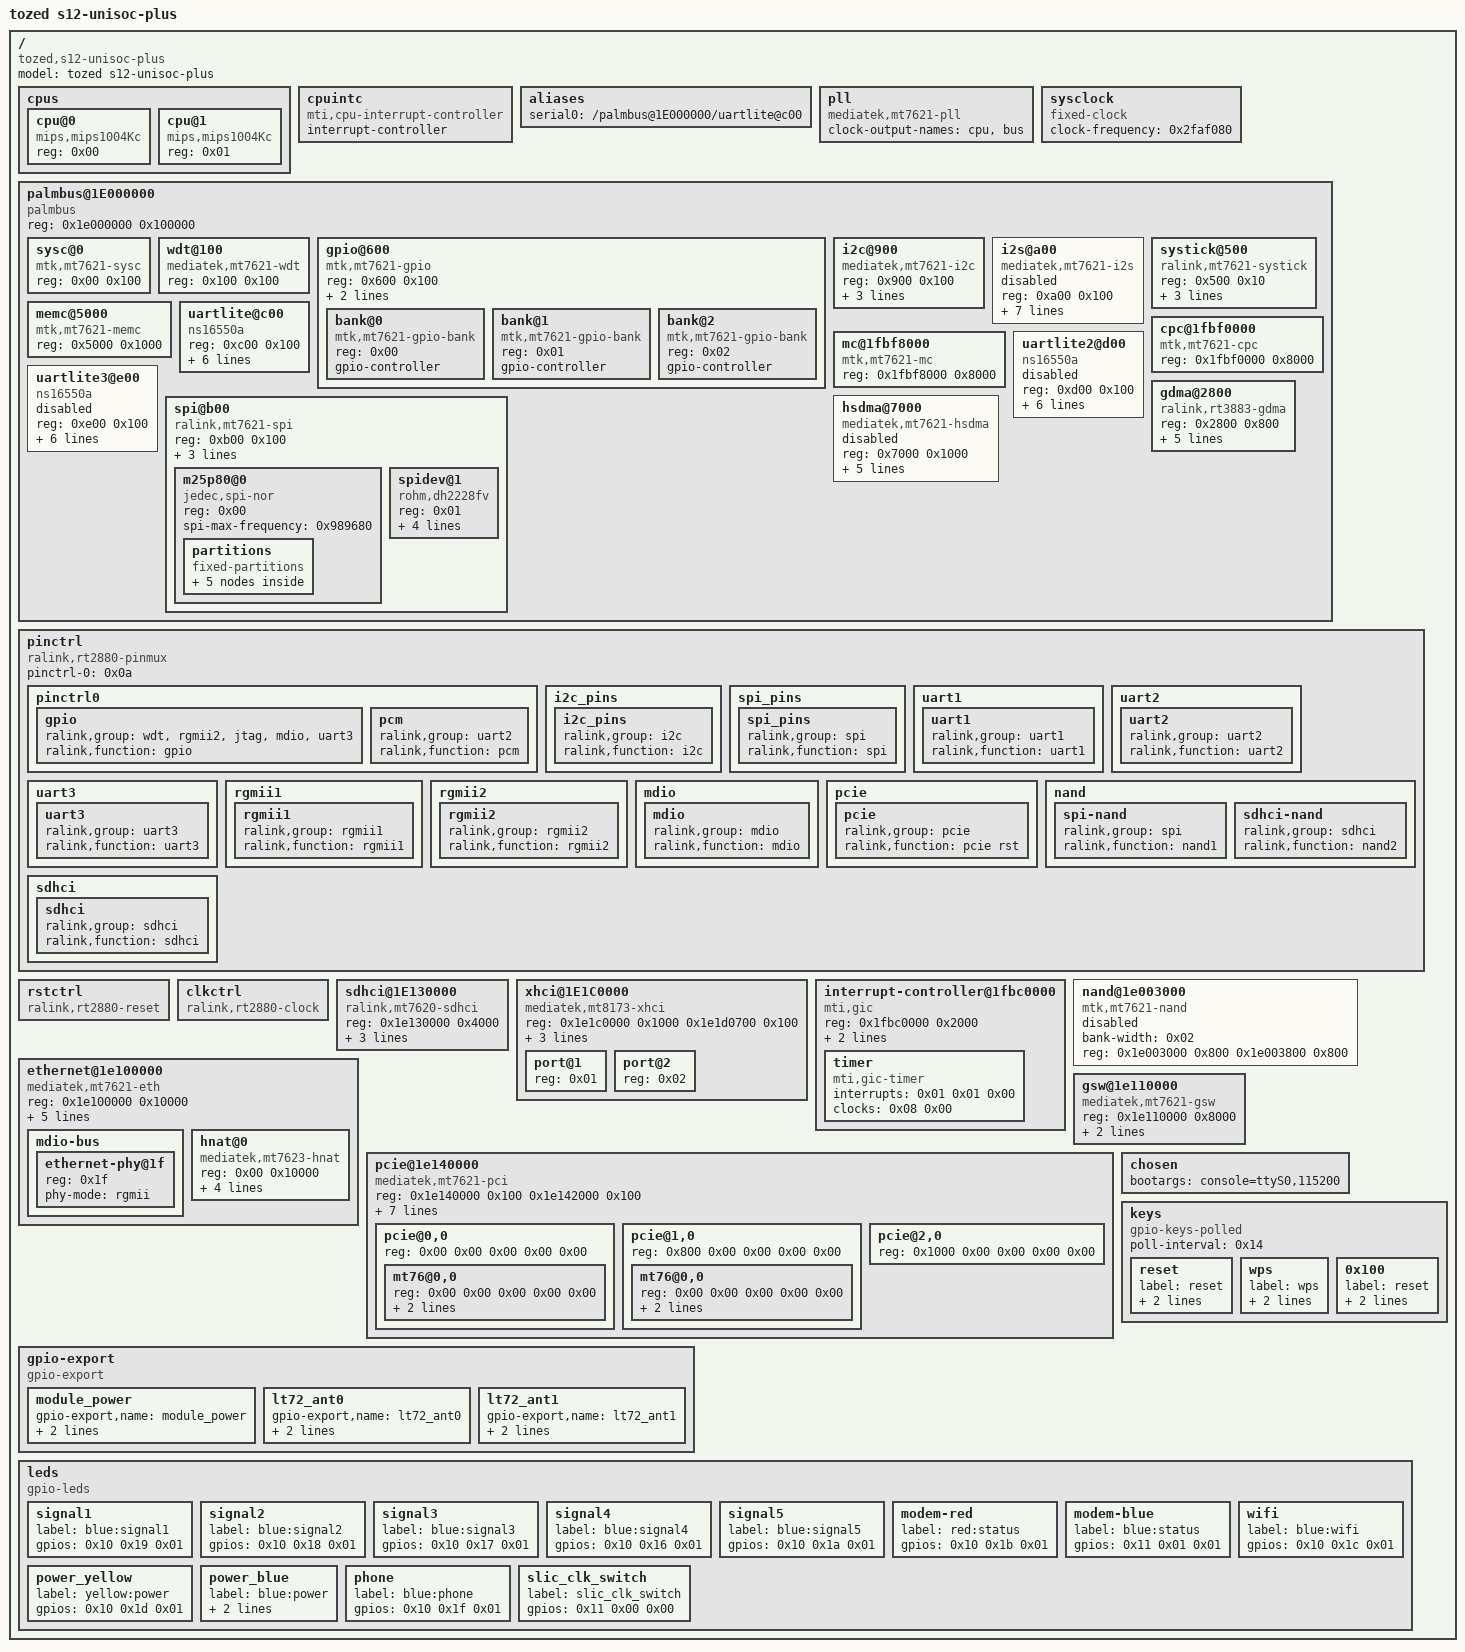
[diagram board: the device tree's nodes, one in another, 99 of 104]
/dts-v1/;

/ {
	#address-cells = <0x01>;
	#size-cells = <0x01>;
	compatible = "tozed,s12-unisoc-plus", "mediatek,mt7621-soc";
	model = "tozed s12-unisoc-plus";

	cpus {
		#address-cells = <0x01>;
		#size-cells = <0x00>;

		cpu@0 {
			device_type = "cpu";
			compatible = "mips,mips1004Kc";
			reg = <0x00>;
		};

		cpu@1 {
			device_type = "cpu";
			compatible = "mips,mips1004Kc";
			reg = <0x01>;
		};
	};

	cpuintc {
		#address-cells = <0x00>;
		#interrupt-cells = <0x01>;
		interrupt-controller;
		compatible = "mti,cpu-interrupt-controller";
	};

	aliases {
		serial0 = "/palmbus@1E000000/uartlite@c00";
	};

	pll {
		compatible = "mediatek,mt7621-pll", "syscon";
		#clock-cells = <0x01>;
		clock-output-names = "cpu", "bus";
		linux,phandle = <0x08>;
		phandle = <0x08>;
	};

	sysclock {
		#clock-cells = <0x00>;
		compatible = "fixed-clock";
		clock-frequency = <0x2faf080>;
		linux,phandle = <0x02>;
		phandle = <0x02>;
	};

	palmbus@1E000000 {
		compatible = "palmbus";
		reg = <0x1e000000 0x100000>;
		ranges = <0x00 0x1e000000 0xfffff>;
		#address-cells = <0x01>;
		#size-cells = <0x01>;

		sysc@0 {
			compatible = "mtk,mt7621-sysc";
			reg = <0x00 0x100>;
		};

		wdt@100 {
			compatible = "mediatek,mt7621-wdt";
			reg = <0x100 0x100>;
		};

		gpio@600 {
			#address-cells = <0x01>;
			#size-cells = <0x00>;
			compatible = "mtk,mt7621-gpio";
			reg = <0x600 0x100>;
			interrupt-parent = <0x01>;
			interrupts = <0x00 0x0c 0x04>;

			bank@0 {
				reg = <0x00>;
				compatible = "mtk,mt7621-gpio-bank";
				gpio-controller;
				#gpio-cells = <0x02>;
				linux,phandle = <0x10>;
				phandle = <0x10>;
			};

			bank@1 {
				reg = <0x01>;
				compatible = "mtk,mt7621-gpio-bank";
				gpio-controller;
				#gpio-cells = <0x02>;
				linux,phandle = <0x11>;
				phandle = <0x11>;
			};

			bank@2 {
				reg = <0x02>;
				compatible = "mtk,mt7621-gpio-bank";
				gpio-controller;
				#gpio-cells = <0x02>;
			};
		};

		i2c@900 {
			compatible = "mediatek,mt7621-i2c";
			reg = <0x900 0x100>;
			clocks = <0x02>;
			resets = <0x03 0x10>;
			reset-names = "i2c";
			#address-cells = <0x01>;
			#size-cells = <0x00>;
			status = "okay";
			pinctrl-names = "default";
			pinctrl-0 = <0x04>;
		};

		i2s@a00 {
			compatible = "mediatek,mt7621-i2s";
			reg = <0xa00 0x100>;
			clocks = <0x02>;
			resets = <0x03 0x11>;
			reset-names = "i2s";
			interrupt-parent = <0x01>;
			interrupts = <0x00 0x10 0x04>;
			txdma-req = <0x02>;
			rxdma-req = <0x03>;
			dmas = <0x05 0x04 0x05 0x06>;
			dma-names = "tx", "rx";
			status = "disabled";
		};

		systick@500 {
			compatible = "ralink,mt7621-systick", "ralink,cevt-systick";
			reg = <0x500 0x10>;
			resets = <0x03 0x1c>;
			reset-names = "intc";
			interrupt-parent = <0x01>;
			interrupts = <0x00 0x05 0x04>;
		};

		memc@5000 {
			compatible = "mtk,mt7621-memc";
			reg = <0x5000 0x1000>;
		};

		cpc@1fbf0000 {
			compatible = "mtk,mt7621-cpc";
			reg = <0x1fbf0000 0x8000>;
		};

		mc@1fbf8000 {
			compatible = "mtk,mt7621-mc";
			reg = <0x1fbf8000 0x8000>;
		};

		uartlite@c00 {
			compatible = "ns16550a";
			reg = <0xc00 0x100>;
			clock-frequency = <0x2faf080>;
			interrupt-parent = <0x01>;
			interrupts = <0x00 0x1a 0x04>;
			reg-shift = <0x02>;
			reg-io-width = <0x04>;
			no-loopback-test;
		};

		uartlite2@d00 {
			compatible = "ns16550a";
			reg = <0xd00 0x100>;
			clock-frequency = <0x2faf080>;
			interrupt-parent = <0x01>;
			interrupts = <0x00 0x1b 0x04>;
			reg-shift = <0x02>;
			reg-io-width = <0x04>;
			pinctrl-names = "default";
			pinctrl-0 = <0x06>;
			status = "disabled";
		};

		uartlite3@e00 {
			compatible = "ns16550a";
			reg = <0xe00 0x100>;
			clock-frequency = <0x2faf080>;
			interrupt-parent = <0x01>;
			interrupts = <0x00 0x1c 0x04>;
			reg-shift = <0x02>;
			reg-io-width = <0x04>;
			pinctrl-names = "default";
			pinctrl-0 = <0x07>;
			status = "disabled";
		};

		spi@b00 {
			status = "okay";
			compatible = "ralink,mt7621-spi";
			reg = <0xb00 0x100>;
			clocks = <0x08 0x01>;
			resets = <0x03 0x12>;
			reset-names = "spi";
			#address-cells = <0x01>;
			#size-cells = <0x00>;
			pinctrl-names = "default";
			pinctrl-0 = <0x09>;

			m25p80@0 {
				compatible = "jedec,spi-nor";
				reg = <0x00>;
				spi-max-frequency = <0x989680>;

				partitions {
					compatible = "fixed-partitions";
					#address-cells = <0x01>;
					#size-cells = <0x01>;

					partition@0 {
						label = "u-boot";
						reg = <0x00 0x30000>;
						read-only;
					};

					partition@30000 {
						label = "u-boot-env";
						reg = <0x30000 0x8000>;
					};

					partition@40000 {
						label = "factory";
						reg = <0x40000 0x10000>;
						linux,phandle = <0x0d>;
						phandle = <0x0d>;
					};

					partition@50000 {
						compatible = "denx,uimage";
						label = "firmware";
						reg = <0x50000 0xfb0000>;
					};

					partition@38000 {
						label = "tozed-conf";
						reg = <0x38000 0x8000>;
					};
				};
			};

			spidev@1 {
				compatible = "rohm,dh2228fv";
				reg = <0x01>;
				linux,modalias = "spidev";
				spi-cpha = <0x01>;
				spi-cpol = <0x01>;
				status = "okay";
				spi-max-frequency = <0x1f4000>;
			};
		};

		gdma@2800 {
			compatible = "ralink,rt3883-gdma";
			reg = <0x2800 0x800>;
			resets = <0x03 0x0e>;
			reset-names = "dma";
			interrupt-parent = <0x01>;
			interrupts = <0x00 0x0d 0x04>;
			#dma-cells = <0x01>;
			#dma-channels = <0x10>;
			#dma-requests = <0x10>;
			status = "okay";
			linux,phandle = <0x05>;
			phandle = <0x05>;
		};

		hsdma@7000 {
			compatible = "mediatek,mt7621-hsdma";
			reg = <0x7000 0x1000>;
			resets = <0x03 0x05>;
			reset-names = "hsdma";
			interrupt-parent = <0x01>;
			interrupts = <0x00 0x0b 0x04>;
			#dma-cells = <0x01>;
			#dma-channels = <0x01>;
			#dma-requests = <0x01>;
			status = "disabled";
		};
	};

	pinctrl {
		compatible = "ralink,rt2880-pinmux";
		pinctrl-names = "default";
		pinctrl-0 = <0x0a>;

		pinctrl0 {
			linux,phandle = <0x0a>;
			phandle = <0x0a>;

			gpio {
				ralink,group = "wdt", "rgmii2", "jtag", "mdio", "uart3";
				ralink,function = "gpio";
			};

			pcm {
				ralink,group = "uart2";
				ralink,function = "pcm";
			};
		};

		i2c_pins {
			linux,phandle = <0x04>;
			phandle = <0x04>;

			i2c_pins {
				ralink,group = "i2c";
				ralink,function = "i2c";
			};
		};

		spi_pins {
			linux,phandle = <0x09>;
			phandle = <0x09>;

			spi_pins {
				ralink,group = "spi";
				ralink,function = "spi";
			};
		};

		uart1 {

			uart1 {
				ralink,group = "uart1";
				ralink,function = "uart1";
			};
		};

		uart2 {
			linux,phandle = <0x06>;
			phandle = <0x06>;

			uart2 {
				ralink,group = "uart2";
				ralink,function = "uart2";
			};
		};

		uart3 {
			linux,phandle = <0x07>;
			phandle = <0x07>;

			uart3 {
				ralink,group = "uart3";
				ralink,function = "uart3";
			};
		};

		rgmii1 {

			rgmii1 {
				ralink,group = "rgmii1";
				ralink,function = "rgmii1";
			};
		};

		rgmii2 {

			rgmii2 {
				ralink,group = "rgmii2";
				ralink,function = "rgmii2";
			};
		};

		mdio {

			mdio {
				ralink,group = "mdio";
				ralink,function = "mdio";
			};
		};

		pcie {
			linux,phandle = <0x0e>;
			phandle = <0x0e>;

			pcie {
				ralink,group = "pcie";
				ralink,function = "pcie rst";
			};
		};

		nand {

			spi-nand {
				ralink,group = "spi";
				ralink,function = "nand1";
			};

			sdhci-nand {
				ralink,group = "sdhci";
				ralink,function = "nand2";
			};
		};

		sdhci {
			linux,phandle = <0x0b>;
			phandle = <0x0b>;

			sdhci {
				ralink,group = "sdhci";
				ralink,function = "sdhci";
			};
		};
	};

	rstctrl {
		compatible = "ralink,rt2880-reset";
		#reset-cells = <0x01>;
		linux,phandle = <0x03>;
		phandle = <0x03>;
	};

	clkctrl {
		compatible = "ralink,rt2880-clock";
		#clock-cells = <0x01>;
		linux,phandle = <0x0f>;
		phandle = <0x0f>;
	};

	sdhci@1E130000 {
		status = "okay";
		compatible = "ralink,mt7620-sdhci";
		reg = <0x1e130000 0x4000>;
		interrupt-parent = <0x01>;
		interrupts = <0x00 0x14 0x04>;
		pinctrl-names = "default";
		pinctrl-0 = <0x0b>;
	};

	xhci@1E1C0000 {
		#address-cells = <0x01>;
		#size-cells = <0x00>;
		status = "okay";
		compatible = "mediatek,mt8173-xhci";
		reg = <0x1e1c0000 0x1000 0x1e1d0700 0x100>;
		reg-names = "mac", "ippc";
		clocks = <0x02>;
		clock-names = "sys_ck";
		interrupt-parent = <0x01>;
		interrupts = <0x00 0x16 0x04>;

		port@1 {
			reg = <0x01>;
			#trigger-source-cells = <0x00>;
		};

		port@2 {
			reg = <0x02>;
			#trigger-source-cells = <0x00>;
		};
	};

	interrupt-controller@1fbc0000 {
		compatible = "mti,gic";
		reg = <0x1fbc0000 0x2000>;
		interrupt-controller;
		#interrupt-cells = <0x03>;
		mti,reserved-cpu-vectors = <0x07>;
		linux,phandle = <0x01>;
		phandle = <0x01>;

		timer {
			compatible = "mti,gic-timer";
			interrupts = <0x01 0x01 0x00>;
			clocks = <0x08 0x00>;
		};
	};

	nand@1e003000 {
		status = "disabled";
		compatible = "mtk,mt7621-nand";
		bank-width = <0x02>;
		reg = <0x1e003000 0x800 0x1e003800 0x800>;
	};

	ethernet@1e100000 {
		compatible = "mediatek,mt7621-eth";
		reg = <0x1e100000 0x10000>;
		#address-cells = <0x01>;
		#size-cells = <0x01>;
		resets = <0x03 0x06 0x03 0x17>;
		reset-names = "fe", "eth";
		interrupt-parent = <0x01>;
		interrupts = <0x00 0x03 0x04>;
		mediatek,switch = <0x0c>;
		mtd-mac-address = <0x0d 0xe000>;

		mdio-bus {
			#address-cells = <0x01>;
			#size-cells = <0x00>;

			ethernet-phy@1f {
				reg = <0x1f>;
				phy-mode = "rgmii";
			};
		};

		hnat@0 {
			compatible = "mediatek,mt7623-hnat";
			reg = <0x00 0x10000>;
			mtketh-ppd = "eth0";
			mtketh-lan = "eth0";
			mtketh-wan = "eth0";
			resets = <0x03 0x00>;
			reset-names = "mtketh";
		};
	};

	gsw@1e110000 {
		compatible = "mediatek,mt7621-gsw";
		reg = <0x1e110000 0x8000>;
		interrupt-parent = <0x01>;
		interrupts = <0x00 0x17 0x04>;
		linux,phandle = <0x0c>;
		phandle = <0x0c>;
	};

	pcie@1e140000 {
		compatible = "mediatek,mt7621-pci";
		reg = <0x1e140000 0x100 0x1e142000 0x100>;
		#address-cells = <0x03>;
		#size-cells = <0x02>;
		pinctrl-names = "default";
		pinctrl-0 = <0x0e>;
		device_type = "pci";
		bus-range = <0x00 0xff>;
		ranges = <0x2000000 0x00 0x00 0x60000000 0x00 0x10000000 0x1000000 0x00 0x00 0x1e160000 0x00 0x10000>;
		interrupt-parent = <0x01>;
		interrupts = <0x00 0x04 0x04 0x00 0x18 0x04 0x00 0x19 0x04>;
		status = "okay";
		resets = <0x03 0x18 0x03 0x19 0x03 0x1a>;
		reset-names = "pcie0", "pcie1", "pcie2";
		clocks = <0x0f 0x18 0x0f 0x19 0x0f 0x1a>;
		clock-names = "pcie0", "pcie1", "pcie2";

		pcie@0,0 {
			reg = <0x00 0x00 0x00 0x00 0x00>;
			#address-cells = <0x03>;
			#size-cells = <0x02>;
			ranges;

			mt76@0,0 {
				reg = <0x00 0x00 0x00 0x00 0x00>;
				mediatek,mtd-eeprom = <0x0d 0x8000>;
				ieee80211-freq-limit = <0x4c4b40 0x5b8d80>;
			};
		};

		pcie@1,0 {
			reg = <0x800 0x00 0x00 0x00 0x00>;
			#address-cells = <0x03>;
			#size-cells = <0x02>;
			ranges;

			mt76@0,0 {
				reg = <0x00 0x00 0x00 0x00 0x00>;
				mediatek,mtd-eeprom = <0x0d 0x00>;
				ieee80211-freq-limit = <0x249f00 0x2625a0>;
			};
		};

		pcie@2,0 {
			reg = <0x1000 0x00 0x00 0x00 0x00>;
			#address-cells = <0x03>;
			#size-cells = <0x02>;
			ranges;
		};
	};

	chosen {
		bootargs = "console=ttyS0,115200";
	};

	gpio-export {
		compatible = "gpio-export";

		module_power {
			gpio-export,name = "module_power";
			gpio-export,output = <0x01>;
			gpios = <0x10 0x0e 0x00>;
		};

		lt72_ant0 {
			gpio-export,name = "lt72_ant0";
			gpio-export,input = <0x00>;
			gpios = <0x10 0x06 0x00>;
		};

		lt72_ant1 {
			gpio-export,name = "lt72_ant1";
			gpio-export,input = <0x00>;
			gpios = <0x10 0x07 0x01>;
		};
	};

	keys {
		compatible = "gpio-keys-polled";
		poll-interval = <0x14>;

		reset {
			label = "reset";
			gpios = <0x10 0x0d 0x01>;
			linux,code = <0x198>;
		};

		wps {
			label = "wps";
			gpios = <0x10 0x12 0x01>;
			linux,code = <0x211>;
		};

		0x100 {
			label = "reset";
			gpios = <0x10 0x0f 0x01>;
			linux,code = <0x100>;
		};
	};

	leds {
		compatible = "gpio-leds";

		signal1 {
			label = "blue:signal1";
			gpios = <0x10 0x19 0x01>;
		};

		signal2 {
			label = "blue:signal2";
			gpios = <0x10 0x18 0x01>;
		};

		signal3 {
			label = "blue:signal3";
			gpios = <0x10 0x17 0x01>;
		};

		signal4 {
			label = "blue:signal4";
			gpios = <0x10 0x16 0x01>;
		};

		signal5 {
			label = "blue:signal5";
			gpios = <0x10 0x1a 0x01>;
		};

		modem-red {
			label = "red:status";
			gpios = <0x10 0x1b 0x01>;
		};

		modem-blue {
			label = "blue:status";
			gpios = <0x11 0x01 0x01>;
		};

		wifi {
			label = "blue:wifi";
			gpios = <0x10 0x1c 0x01>;
		};

		power_yellow {
			label = "yellow:power";
			gpios = <0x10 0x1d 0x01>;
		};

		power_blue {
			label = "blue:power";
			gpios = <0x10 0x10 0x01>;
			default-state = "on";
		};

		phone {
			label = "blue:phone";
			gpios = <0x10 0x1f 0x01>;
		};

		slic_clk_switch {
			label = "slic_clk_switch";
			gpios = <0x11 0x00 0x00>;
		};
	};
};
